# DSS_CTRL register map
Vendor: Texas Instruments
Peripheral module from a debugger description file (folder awr2544).
Registers are 32-bit, read-write, no defined reset value unless marked. A register's access mark holds for its fields unless they carry their own. Offsets are as the file gives them; lines under a group give offsets from that group; [hi:lo] are bit positions; {n}, {i} and the like mark numbered series; 'fields as' and 'values as' point back to an identical list; <NAME> marks a mode.

## DSS_CTRL
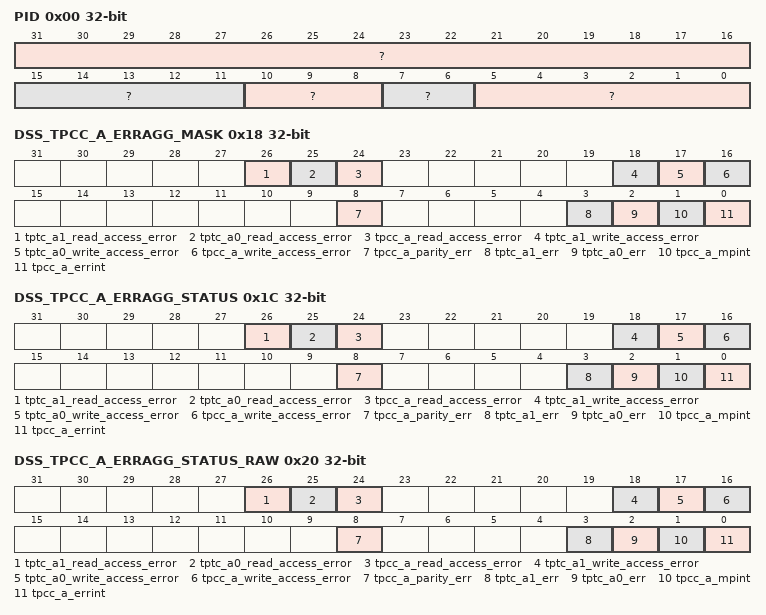
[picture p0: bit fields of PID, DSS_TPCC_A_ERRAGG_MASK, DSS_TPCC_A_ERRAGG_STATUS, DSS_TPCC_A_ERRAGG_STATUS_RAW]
0x00 PID ro
  [31:16] ?, [15:11] ?, [10:8] ?, [7:6] ?, [5:0] ?
0x04 HW_REG0
  [31:0] hwreg0 — Reserved for R&D
0x08 HW_REG1
  [31:0] hwreg1 — Reserved for R&D
0x0C PREVIOUS_NAME
  [31:0] hwreg2 — Reserved for R&D
0x10 HW_REG3
  [31:0] hwreg3 — Reserved for R&D
0x14 DSS_SW_INT
  [3:0] dss_swint — Write pulse bit field: DSS SW Interrupt Write 1 : Generate an interrupt on DSS_SW_INT0
0x18 DSS_TPCC_A_ERRAGG_MASK
  [26] tptc_a1_read_access_error — Mask Interrupt from DSS_TPTC_A1 to aggregated Interrupt DSS_TPCC_A_INTAGG 1 : Interrupt is Masked 0 : Interrupt is Unmasked
  [25] tptc_a0_read_access_error — Mask Interrupt from DSS_TPTC_A0 to aggregated Interrupt DSS_TPCC_A_INTAGG 1 : Interrupt is Masked 0 : Interrupt is Unmasked
  [24] tpcc_a_read_access_error — Mask Interrupt from DSS_TPCC_A to aggregated Interrupt DSS_TPCC_A_INTAGG 1 : Interrupt is Masked 0 : Interrupt is Unmasked
  [18] tptc_a1_write_access_error — Mask Interrupt from DSS_TPTC_A1 to aggregated Interrupt DSS_TPTC_A_INTAGG 1 : Interrupt is Masked 0 : Interrupt is Unmasked
  [17] tptc_a0_write_access_error — Mask Interrupt from DSS_TPTC_A0 to aggregated Interrupt DSS_TPTC_A_INTAGG 1 : Interrupt is Masked 0 : Interrupt is Unmasked
  [16] tpcc_a_write_access_error — Mask Interrupt from DSS_TPCC_A to aggregated Interrupt DSS_TPCC_A_INTAGG 1 : Interrupt is Masked 0 : Interrupt is Unmasked
  [8] tpcc_a_parity_err — Mask Interrupt from DSS_TPCC_A to aggregated Interrupt DSS_TPCC_A_INTAGG 1 : Interrupt is Masked 0 : Interrupt is Unmasked
  [3] tptc_a1_err — Mask Interrupt from DSS_TPTC_A1 to aggregated Interrupt DSS_TPCC_A_INTAGG 1 : Interrupt is Masked 0 : Interrupt is Unmasked
  [2] tptc_a0_err — Mask Interrupt from DSS_TPTC_A0 to aggregated Interrupt DSS_TPCC_A_INTAGG 1 : Interrupt is Masked 0 : Interrupt is Unmasked
  [1] tpcc_a_mpint — Mask Interrupt from DSS_TPCC_A to aggregated Interrupt DSS_TPCC_A_INTAGG 1 : Interrupt is Masked 0 : Interrupt is Unmasked
  [0] tpcc_a_errint — Mask Interrupt from DSS_TPCC_A to aggregated Interrupt DSS_TPCC_A_INTAGG 1 : Interrupt is Masked 0 : Interrupt is Unmasked
0x1C DSS_TPCC_A_ERRAGG_STATUS
  [26] tptc_a1_read_access_error — Status of Interrupt from DSS_TPTC_A1. Set only if Interupt is unmasked in DSS_TPCC_A_INTAGG_MASK Wrie 0x1 to clear this interrupt.
  [25] tptc_a0_read_access_error — Status of Interrupt from DSS_TPTC_A0. Set only if Interupt is unmasked in DSS_TPCC_A_INTAGG_MASK Wrie 0x1 to clear this interrupt.
  [24] tpcc_a_read_access_error — Status of Interrupt from DSS_TPCC_A. Set only if Interupt is unmasked in DSS_TPCC_A_INTAGG_MASK Wrie 0x1 to clear this interrupt.
  [18] tptc_a1_write_access_error — Status of Interrupt from DSS_TPTC_A1. Set only if Interupt is unmasked in DSS_TPTC_A_INTAGG_MASK Wrie 0x1 to clear this interrupt.
  [17] tptc_a0_write_access_error — Status of Interrupt from DSS_TPTC_A0. Set only if Interupt is unmasked in DSS_TPTC_A_INTAGG_MASK Wrie 0x1 to clear this interrupt.
  [16] tpcc_a_write_access_error — Status of Interrupt from DSS_TPCC_A. Set only if Interupt is unmasked in DSS_TPCC_A_INTAGG_MASK Wrie 0x1 to clear this interrupt.
  [8] tpcc_a_parity_err — Status of Interrupt from DSS_TPCC_A. Set only if Interupt is unmasked in DSS_TPCC_A_INTAGG_MASK Wrie 0x1 to clear this interrupt.
  [3] tptc_a1_err — Status of Interrupt from DSS_TPTC_A1. Set only if Interupt is unmasked in DSS_TPCC_A_INTAGG_MASK Wrie 0x1 to clear this interrupt.
  [2] tptc_a0_err — Status of Interrupt from DSS_TPTC_A0. Set only if Interupt is unmasked in DSS_TPCC_A_INTAGG_MASK Wrie 0x1 to clear this interrupt.
  [1] tpcc_a_mpint — Status of Interrupt from DSS_TPCC_A. Set only if Interupt is unmasked in DSS_TPCC_A_INTAGG_MASK Wrie 0x1 to clear this interrupt.
  [0] tpcc_a_errint — Status of Interrupt from DSS_TPCC_A. Set only if Interupt is unmasked in DSS_TPCC_A_INTAGG_MASK Wrie 0x1 to clear this interrupt.
0x20 DSS_TPCC_A_ERRAGG_STATUS_RAW
  [26] tptc_a1_read_access_error — Raw Status of Interrupt from DSS_TPTC_A1. Set irrespective if the Interupt is masked or unmasked in DSS_TPCC_A_INTAGG_MASK
  [25] tptc_a0_read_access_error — Raw Status of Interrupt from DSS_TPTC_A0. Set irrespective if the Interupt is masked or unmasked in DSS_TPCC_A_INTAGG_MASK
  [24] tpcc_a_read_access_error — Raw Status of Interrupt from DSS_TPCC_A. Set irrespective if the Interupt is masked or unmasked in DSS_TPCC_A_INTAGG_MASK
  [18] tptc_a1_write_access_error — Raw Status of Interrupt from DSS_TPTC_A1. Set irrespective if the Interupt is masked or unmasked in DSS_TPTC_A_INTAGG_MASK
  [17] tptc_a0_write_access_error — Raw Status of Interrupt from DSS_TPTC_A0. Set irrespective if the Interupt is masked or unmasked in DSS_TPTC_A_INTAGG_MASK
  [16] tpcc_a_write_access_error — Raw Status of Interrupt from DSS_TPCC_A. Set irrespective if the Interupt is masked or unmasked in DSS_TPCC_A_INTAGG_MASK
  [8] tpcc_a_parity_err — Raw Status of Interrupt from DSS_TPCC_A. Set irrespective if the Interupt is masked or unmasked in DSS_TPCC_A_INTAGG_MASK
  [3] tptc_a1_err — Raw Status of Interrupt from DSS_TPTC_A1. Set irrespective if the Interupt is masked or unmasked in DSS_TPCC_A_INTAGG_MASK
  [2] tptc_a0_err — Raw Status of Interrupt from DSS_TPTC_A0. Set irrespective if the Interupt is masked or unmasked in DSS_TPCC_A_INTAGG_MASK
  [1] tpcc_a_mpint — Raw Status of Interrupt from DSS_TPCC_A. Set irrespective if the Interupt is masked or unmasked in DSS_TPCC_A_INTAGG_MASK
  [0] tpcc_a_errint — Raw Status of Interrupt from DSS_TPCC_A. Set irrespective if the Interupt is masked or unmasked in DSS_TPCC_A_INTAGG_MASK
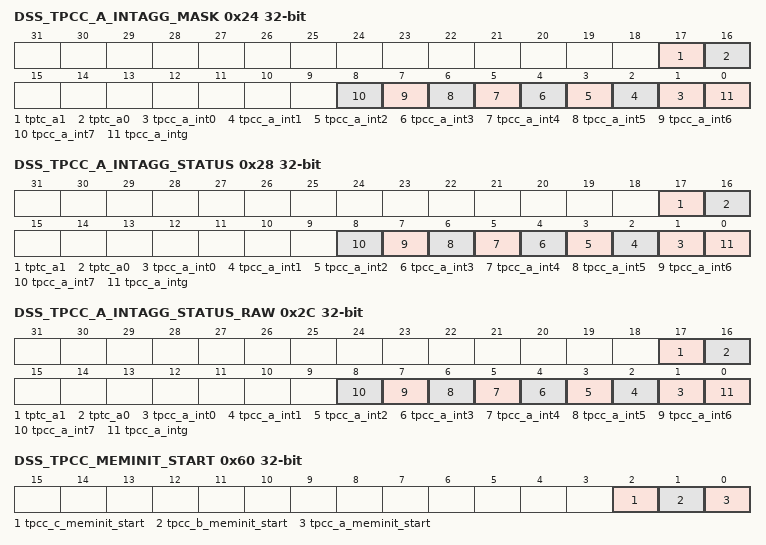
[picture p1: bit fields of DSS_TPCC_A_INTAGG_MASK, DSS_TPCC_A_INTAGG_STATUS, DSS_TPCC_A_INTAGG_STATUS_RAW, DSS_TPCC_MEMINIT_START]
0x24 DSS_TPCC_A_INTAGG_MASK
  [17] tptc_a1 — Mask Interrupt from DSS_TPTC_A1 to aggregated Interrupt DSS_TPCC_A_INTAGG 1 : Interrupt is Masked 0 : Interrupt is Unmasked
  [16] tptc_a0 — Mask Interrupt from DSS_TPTC_A0 to aggregated Interrupt DSS_TPCC_A_INTAGG 1 : Interrupt is Masked 0 : Interrupt is Unmasked
  [n+1] tpcc_a_int{n} (n=0..7) — Mask Interrupt from DSS_TPCC_A to aggregated Interrupt DSS_TPCC_A_INTAGG 1 : Interrupt is Masked 0 : Interrupt is Unmasked
  [0] tpcc_a_intg — Mask Interrupt from DSS_TPCC_A to aggregated Interrupt DSS_TPCC_A_INTAGG 1 : Interrupt is Masked 0 : Interrupt is Unmasked
0x28 DSS_TPCC_A_INTAGG_STATUS
  [17] tptc_a1 — Status of Interrupt from DSS_TPTC_A1. Set only if Interupt is unmasked in DSS_TPCC_A_INTAGG_MASK Wrie 0x1 to clear this interrupt.
  [16] tptc_a0 — Status of Interrupt from DSS_TPTC_A0. Set only if Interupt is unmasked in DSS_TPCC_A_INTAGG_MASK Wrie 0x1 to clear this interrupt.
  [n+1] tpcc_a_int{n} (n=0..7) — Status of Interrupt from DSS_TPCC_A. Set only if Interupt is unmasked in DSS_TPCC_A_INTAGG_MASK Wrie 0x1 to clear this interrupt.
  [0] tpcc_a_intg — Status of Interrupt from DSS_TPCC_A. Set only if Interupt is unmasked in DSS_TPCC_A_INTAGG_MASK Wrie 0x1 to clear this interrupt.
0x2C DSS_TPCC_A_INTAGG_STATUS_RAW
  [17] tptc_a1 — Raw Status of Interrupt from DSS_TPTC_A1. Set irrespective if the Interupt is masked or unmasked in DSS_TPCC_A_INTAGG_MASK
  [16] tptc_a0 — Raw Status of Interrupt from DSS_TPTC_A0. Set irrespective if the Interupt is masked or unmasked in DSS_TPCC_A_INTAGG_MASK
  [n+1] tpcc_a_int{n} (n=0..7) — Raw Status of Interrupt from DSS_TPCC_A. Set irrespective if the Interupt is masked or unmasked in DSS_TPCC_A_INTAGG_MASK
  [0] tpcc_a_intg — Raw Status of Interrupt from DSS_TPCC_A. Set irrespective if the Interupt is masked or unmasked in DSS_TPCC_A_INTAGG_MASK
0x60 DSS_TPCC_MEMINIT_START
  [2] tpcc_c_meminit_start — RESERVED: Dont Use
  [1] tpcc_b_meminit_start — RESERVED: Dont Use
  [0] tpcc_a_meminit_start — Write pulse bit field: Start Memory intialization of TPCC A Param memory. Write 0x1 to start memory initilization. Write 0x0 after ensuring Memory intilization is in progress or has completed. Before starting new initilzation sequence ensure that there is no initilization sequence is in progress (ie TPCC_A_MEMINIT_STATUS should be 0x0) and clear any previouls complettion status(ie write 0x1 to clear TPCC_A_MEMINIT_DONE)
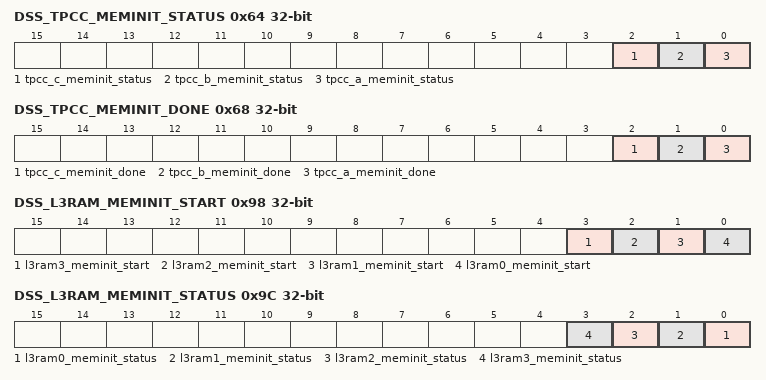
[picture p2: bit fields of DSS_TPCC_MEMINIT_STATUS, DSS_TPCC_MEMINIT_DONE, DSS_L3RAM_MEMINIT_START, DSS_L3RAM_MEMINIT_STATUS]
0x64 DSS_TPCC_MEMINIT_STATUS ro
  [2] tpcc_c_meminit_status — RESERVED: Dont Use
  [1] tpcc_b_meminit_status — RESERVED: Dont Use
  [0] tpcc_a_meminit_status — Status field. Read value 0x1 indicates previously triggered Memory intialization of TPCC A Param memory is in progress.
0x68 DSS_TPCC_MEMINIT_DONE
  [2] tpcc_c_meminit_done — RESERVED: Dont Use
  [1] tpcc_b_meminit_done — RESERVED: Dont Use
  [0] tpcc_a_meminit_done — Status field. Read value 0x1 indicates previously triggered Memory intialization of TPCC A Param memory is complte. Write 0x1 to clear status. Refer TPCC Memory initialization sequnce in EDMA section for more details
0x98 DSS_L3RAM_MEMINIT_START
  [3] l3ram3_meminit_start — Start Memory intialization of TPCC A Param memory. Write 0x1 to start memory initilization. Write 0x0 after ensuring Memory intilization is in progress or has completed. Before starting new initilzation sequence ensure that there is no initilization sequence is in progress (ie L3RAM_MEMINIT_STATUS should be 0x0) and clear any previouls complettion status(ie write 0x1 to clear L3RAM_MEMINIT_DONE)
  [2] l3ram2_meminit_start — Write pulse bit field: Start Memory intialization of TPCC A Param memory. Write 0x1 to start memory initilization. Write 0x0 after ensuring Memory intilization is in progress or has completed. Before starting new initilzation sequence ensure that there is no initilization sequence is in progress (ie L3RAM_MEMINIT_STATUS should be 0x0) and clear any previouls complettion status(ie write 0x1 to clear L3RAM_MEMINIT_DONE)
  [1] l3ram1_meminit_start — Write pulse bit field: Start Memory intialization of TPCC A Param memory. Write 0x1 to start memory initilization. Write 0x0 after ensuring Memory intilization is in progress or has completed. Before starting new initilzation sequence ensure that there is no initilization sequence is in progress (ie L3RAM_MEMINIT_STATUS should be 0x0) and clear any previouls complettion status(ie write 0x1 to clear L3RAM_MEMINIT_DONE)
  [0] l3ram0_meminit_start — Write pulse bit field: Start Memory intialization of TPCC A Param memory. Write 0x1 to start memory initilization. Write 0x0 after ensuring Memory intilization is in progress or has completed. Before starting new initilzation sequence ensure that there is no initilization sequence is in progress (ie L3RAM_MEMINIT_STATUS should be 0x0) and clear any previouls complettion status(ie write 0x1 to clear L3RAM_MEMINIT_DONE)
0x9C DSS_L3RAM_MEMINIT_STATUS ro
  [n] l3ram{n}_meminit_status (n=0..3) — Status field. Read value 0x1 indicates previously triggered Memory intialization of TPCC A Param memory is in progress.
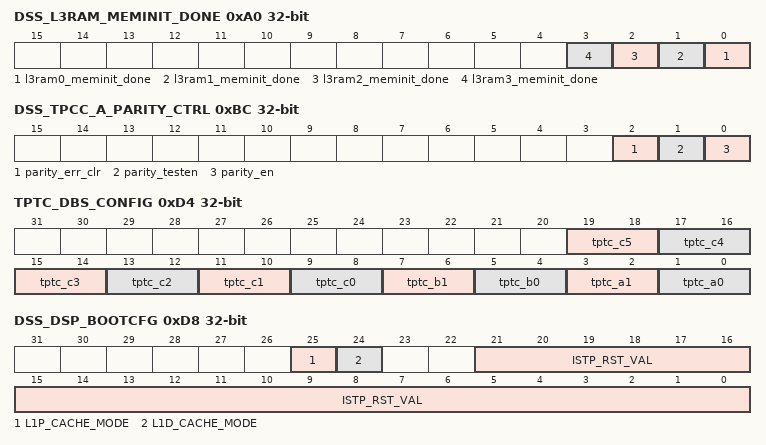
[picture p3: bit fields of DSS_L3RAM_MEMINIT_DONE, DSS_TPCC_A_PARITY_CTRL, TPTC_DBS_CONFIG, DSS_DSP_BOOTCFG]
0xA0 DSS_L3RAM_MEMINIT_DONE
  [n] l3ram{n}_meminit_done (n=0..3) — Status field. Read value 0x1 indicates previously triggered Memory intialization of TPCC A Param memory is complte. Write 0x1 to clear status. Refer TPCC Memory initialization sequnce in EDMA section for more details
0xBC DSS_TPCC_A_PARITY_CTRL
  [2] parity_err_clr — Write pulse bit field: Write 0x1 to clear the Parit Error status for TPCC
  [1] parity_testen — Enable Parity Test for TPCC. Write 0x1 : Parity Test is enabled on PARAM memory
  [0] parity_en — Enable Parity for TPCC. Write 0x1 : Parity is enabled on PARAM memory
0xC8 DSS_TPCC_A_PARITY_STATUS ro
  [7:0] parity_addr — TPCC Error Address at which Parity Error occurred
0xD4 TPTC_DBS_CONFIG
  [2n+9:2n+8] tptc_c{n} (n=1..5) — RESERVED: Dont Use
  [9:8] tptc_c0 — RESERVED: Dont Use0
  [7:6] tptc_b1 — RESERVED: Dont Use
  [5:4] tptc_b0 — RESERVED: Dont Use
  [3:2] tptc_a1 — Max Burst size tieoff value for TPTC A1
  [1:0] tptc_a0 — Max Burst size tieoff value for TPTC A0
0xD8 DSS_DSP_BOOTCFG
  [25] L1P_CACHE_MODE — DSP Boot Configuration : L1P Cache Mode
  [24] L1D_CACHE_MODE — DSP Boot Configuration : L1D Cache Mode
  [21:0] ISTP_RST_VAL — DSP Boot Configuration : Reset Vector
0xDC DSS_DSP_NMI_GATE
  [2:0] gate — Write 3b111 to gate the Non Maskable Interrupt to the DSP. This is not expected to be used
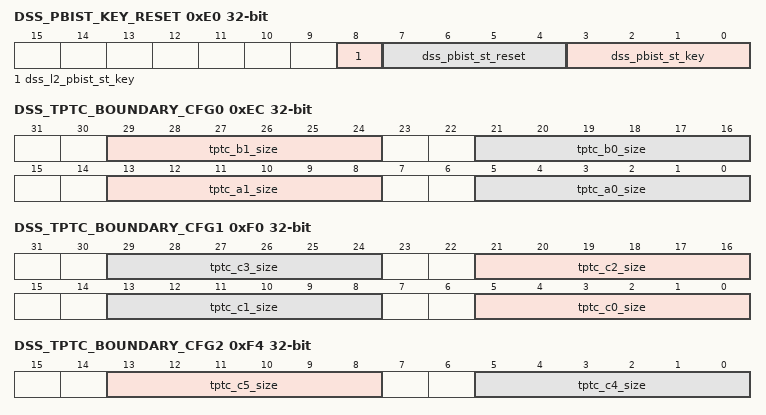
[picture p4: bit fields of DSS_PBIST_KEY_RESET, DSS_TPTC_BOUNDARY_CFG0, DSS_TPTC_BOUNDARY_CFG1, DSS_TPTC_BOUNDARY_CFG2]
0xE0 DSS_PBIST_KEY_RESET
  [8] dss_l2_pbist_st_key — DSS L2 PBIST Selftest Key.
  [7:4] dss_pbist_st_reset — DSS PBIST controller will be brought out of reset when value is 0xA
  [3:0] dss_pbist_st_key — DSS PBIST Selftest Key. Valid value is 0x5
0xE4 DSS_PBIST_REG0
  [31:0] dss_pbist_reg0 — DSP PBIST registers
0xE8 DSS_PBIST_REG1
  [31:0] dss_pbist_reg1 — DSP PBIST registers
0xEC DSS_TPTC_BOUNDARY_CFG0
  [29:24] tptc_b1_size — RESERVED: Dont Use
  [21:16] tptc_b0_size — RESERVED: Dont Use
  [13:8] tptc_a1_size — 6 bit signal used for deciding the boundary crossing size for CID-RID-SID reordering of TPTC Example: writing 6d19 decidies boundary to be 2^19 i.e. 512 KB
  [5:0] tptc_a0_size — 6 bit signal used for deciding the boundary crossing size for CID-RID-SID reordering of TPTC Example: writing 6d19 decidies boundary to be 2^19 i.e. 512 KB
0xF0 DSS_TPTC_BOUNDARY_CFG1
  [8n+5:8n] tptc_c{n}_size (n=0..3) — RESERVED: Dont Use
0xF4 DSS_TPTC_BOUNDARY_CFG2
  [13:8] tptc_c5_size — RESERVED: Dont Use
  [5:0] tptc_c4_size — RESERVED: Dont Use
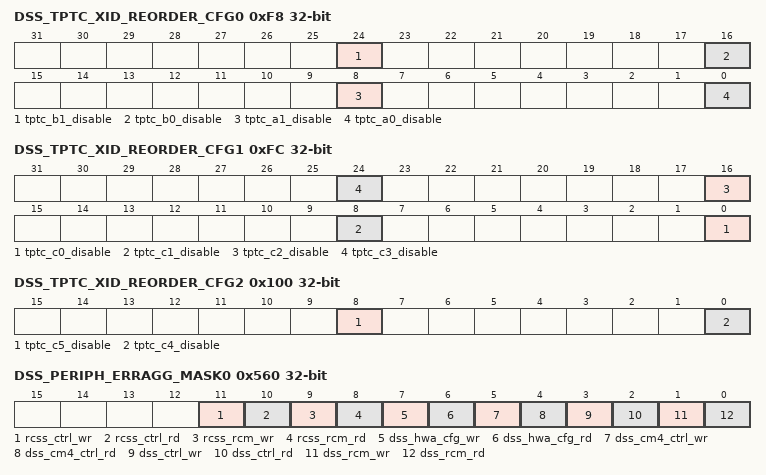
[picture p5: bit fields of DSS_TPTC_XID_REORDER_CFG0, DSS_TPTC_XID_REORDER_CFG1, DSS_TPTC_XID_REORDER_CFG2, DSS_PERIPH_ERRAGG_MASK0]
0xF8 DSS_TPTC_XID_REORDER_CFG0
  [24] tptc_b1_disable — RESERVED: Dont Use
  [16] tptc_b0_disable — RESERVED: Dont Use
  [8] tptc_a1_disable — Writing 1b1 will disable the CID-RID-SID reodering feature for the TPTC instance
  [0] tptc_a0_disable — Writing 1b1 will disable the CID-RID-SID reodering feature for the TPTC instance
0xFC DSS_TPTC_XID_REORDER_CFG1
  [8n] tptc_c{n}_disable (n=0..3) — RESERVED: Dont Use
0x100 DSS_TPTC_XID_REORDER_CFG2
  [8] tptc_c5_disable — RESERVED: Dont Use
  [0] tptc_c4_disable — RESERVED: Dont Use
{0x108+4i} ESM_GATING{i} (i=0..3)
  [31:0] esm_gating — Bit3:0 : writing 000 will ungate the DSS ESM Group2 Error {8i} Bit7:4 : writing 000 will ungate the DSS ESM Group2 Error {8i+1} Bit31:28 : writing 000 will ungate the DSS ESM Group2 Error {8i+7}
0x560 DSS_PERIPH_ERRAGG_MASK0
  [11] rcss_ctrl_wr — Mask the Write error from RCSS_CTRL space from generating an error DSS_PERIPH_ERRAGG to the Processor
  [10] rcss_ctrl_rd — Mask the Read error from RCSS_CTRL space from generating an error DSS_PERIPH_ERRAGG to the Processor
  [9] rcss_rcm_wr — Mask the Write error from RCSS_RCM space from generating an error DSS_PERIPH_ERRAGG to the Processor
  [8] rcss_rcm_rd — Mask the Read error from RCSS_RCM space from generating an error DSS_PERIPH_ERRAGG to the Processor
  [7] dss_hwa_cfg_wr — Mask the Write error from DSS_HWA_CFG space from generating an error DSS_PERIPH_ERRAGG to the Processor
  [6] dss_hwa_cfg_rd — Mask the Read error from DSS_HWA_CFG space from generating an error DSS_PERIPH_ERRAGG to the Processor
  [5] dss_cm4_ctrl_wr — Mask the Write error from DSS_CM4_CTRL space from generating an error DSS_PERIPH_ERRAGG to the Processor
  [4] dss_cm4_ctrl_rd — Mask the Read error from DSS_CM4_CTRL space from generating an error DSS_PERIPH_ERRAGG to the Processor
  [3] dss_ctrl_wr — Mask the Write error from DSS_CTRL space from generating an error DSS_PERIPH_ERRAGG to the Processor
  [2] dss_ctrl_rd — Mask the Read error from DSS_CTRL space from generating an error DSS_PERIPH_ERRAGG to the Processor
  [1] dss_rcm_wr — Mask the Write error from DSS_RCM space from generating an error DSS_PERIPH_ERRAGG to the Processor
  [0] dss_rcm_rd — Mask the Read error from DSS_RCM space from generating an error DSS_PERIPH_ERRAGG to the Processor
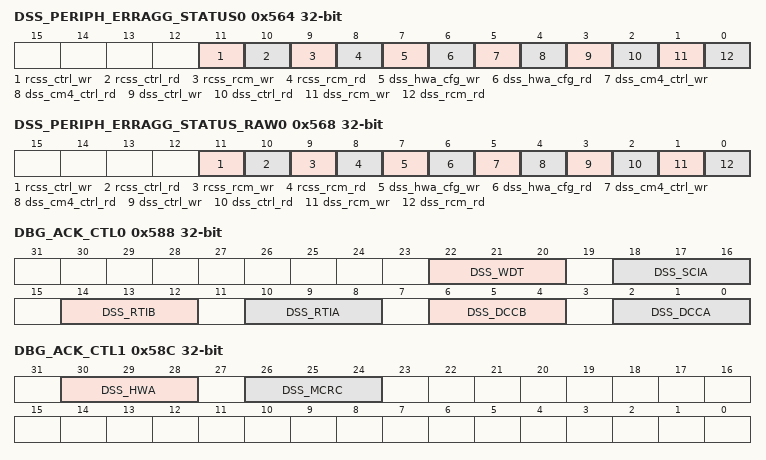
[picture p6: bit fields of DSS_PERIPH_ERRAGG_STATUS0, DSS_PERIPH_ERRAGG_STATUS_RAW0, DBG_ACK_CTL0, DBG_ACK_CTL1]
0x564 DSS_PERIPH_ERRAGG_STATUS0
  [11] rcss_ctrl_wr — Status of the Write error from RCSS_CTRL space. Read 1 : Read error occurred on access to the RCSS_CTRL space
  [10] rcss_ctrl_rd — Status of the Read error from RCSS_CTRL space. Read 1 : Read error occurred on access to the RCSS_CTRL space
  [9] rcss_rcm_wr — Status of the Write error from RCSS_RCM space. Read 1 : Read error occurred on access to the RCSS_RCM space
  [8] rcss_rcm_rd — Status of the Read error from RCSS_RCM space. Read 1 : Read error occurred on access to the RCSS_RCM space
  [7] dss_hwa_cfg_wr — Status of the Write error from DSS_HWA_CFG space. Read 1 : Read error occurred on access to the DSS_HWA_CFG space
  [6] dss_hwa_cfg_rd — Status of the Read error from DSS_HWA_CFG space. Read 1 : Read error occurred on access to the DSS_HWA_CFG space
  [5] dss_cm4_ctrl_wr — Status of the Write error from DSS_CM4_CTRL space. Read 1 : Read error occurred on access to the DSS_CM4_CTRL space
  [4] dss_cm4_ctrl_rd — Status of the Read error from DSS_CM4_CTRL space. Read 1 : Read error occurred on access to the DSS_CM4_CTRL space
  [3] dss_ctrl_wr — Status of the Write error from DSS_CTRL space. Read 1 : Read error occurred on access to the DSS_CTRL space
  [2] dss_ctrl_rd — Status of the Read error from DSS_CTRL space. Read 1 : Read error occurred on access to the DSS_CTRL space
  [1] dss_rcm_wr — Status of the Write error from DSS_RCM space. Read 1 : Read error occurred on access to the DSS_RCM space
  [0] dss_rcm_rd — Status of the Read error from DSS_RCM space. Read 1 : Read error occurred on access to the DSS_RCM space
0x568 DSS_PERIPH_ERRAGG_STATUS_RAW0
  [11] rcss_ctrl_wr — Raw Status of the Write error from RCSS_CTRL space irrespective of it being masked. Read 1 : Read error occurred on access to the RCSS_CTRL space
  [10] rcss_ctrl_rd — Raw Status of the Read error from RCSS_CTRL space irrespective of it being masked. Read 1 : Read error occurred on access to the RCSS_CTRL space
  [9] rcss_rcm_wr — Raw Status of the Write error from RCSS_RCM space irrespective of it being masked. Read 1 : Read error occurred on access to the RCSS_RCM space
  [8] rcss_rcm_rd — Raw Status of the Read error from RCSS_RCM space irrespective of it being masked. Read 1 : Read error occurred on access to the RCSS_RCM space
  [7] dss_hwa_cfg_wr — Raw Status of the Write error from DSS_HWA_CFG space irrespective of it being masked. Read 1 : Read error occurred on access to the DSS_HWA_CFG space
  [6] dss_hwa_cfg_rd — Raw Status of the Read error from DSS_HWA_CFG space irrespective of it being masked. Read 1 : Read error occurred on access to the DSS_HWA_CFG space
  [5] dss_cm4_ctrl_wr — Raw Status of the Write error from DSS_CM4_CTRL space irrespective of it being masked. Read 1 : Read error occurred on access to the DSS_CM4_CTRL space
  [4] dss_cm4_ctrl_rd — Raw Status of the Read error from DSS_CM4_CTRL space irrespective of it being masked. Read 1 : Read error occurred on access to the DSS_CM4_CTRL space
  [3] dss_ctrl_wr — Raw Status of the Write error from DSS_CTRL space irrespective of it being masked. Read 1 : Read error occurred on access to the DSS_CTRL space
  [2] dss_ctrl_rd — Raw Status of the Read error from DSS_CTRL space irrespective of it being masked. Read 1 : Read error occurred on access to the DSS_CTRL space
  [1] dss_rcm_wr — Raw Status of the Write error from DSS_RCM space irrespective of it being masked. Read 1 : Read error occurred on access to the DSS_RCM space
  [0] dss_rcm_rd — Raw Status of the Read error from DSS_RCM space irrespective of it being masked. Read 1 : Read error occurred on access to the DSS_RCM space
0x584 DBG_ACK_CPU_CTRL
  [0] sel — Select the Processor Suspend that is used to Suspend the DSS Peripehrals 0: DSP 1:MSS CR5
0x588 DBG_ACK_CTL0
  [22:20] DSS_WDT — RESERVED: Dont Use
  [18:16] DSS_SCIA — RESERVED: Dont Use
  [14:12] DSS_RTIB — RESERVED: Dont Use
  [10:8] DSS_RTIA — ERESERVED: Dont Use
  [6:4] DSS_DCCB — RESERVED: Dont Use
  [2:0] DSS_DCCA — RESERVED: Dont Use
0x58C DBG_ACK_CTL1
  [30:28] DSS_HWA — Enable Suspend control for the peripheral. 0 :Peripheral not suspended along with processor 1: Peripehal Suspended along with procesor
  [26:24] DSS_MCRC — Enable Suspend control for the peripheral. 0 :Peripheral not suspended along with processor 1: Peripehal Suspended along with procesor
0x590 DSS_DSP_INT_SEL
  [2:0] RCSS_CSI2_ICSSM — DSS DSP Interrupt selcet 0x0: CSI2 Interrupts are propagated to DSP 0x7 : ICSSM Interrupts are propagted to DSP
0x594 DSS_CBUFF_TRIGGER_SEL
  [6:0] sel — DSS CBUFF HW Trigger select from DSS DSP Interrupt Map. Reset value selects RSS_ADC_CAPTURE_COMPLETE as cbuff trigger
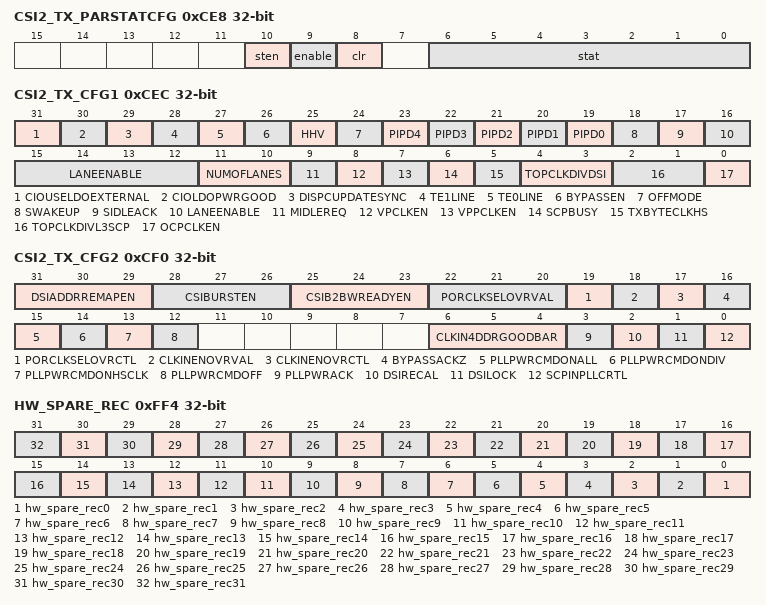
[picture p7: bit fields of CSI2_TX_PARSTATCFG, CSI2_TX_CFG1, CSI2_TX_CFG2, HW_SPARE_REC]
0xCE8 CSI2_TX_PARSTATCFG access per field
  [10] sten rw — Enable bit for the self test of the Parity logic in CSI2
  [9] enable rw — Enable bit for the Parity computation in CSI2
  [8] clr rw — Clear bit for the Parity error from CSI2
  [6:0] stat ro — Parity address from CSI2
0xCEC CSI2_TX_CFG1 access per field
  [31] CIOUSELDOEXTERNAL ro — Connected to dsi_protocol port name csi_ciouseldoexternal
  [30] CIOLDOPWRGOOD rw — Connected to dsi_protocol port name csi_cioldopwrgood
  [29] DISPCUPDATESYNC rw — Connected to dsi_protocol port name csi_dispcupdatesync
  [28] TE1LINE rw — Connected to dsi_protocol port name csi_te1line
  [27] TE0LINE rw — Connected to dsi_protocol port name csi_te0line
  [26] BYPASSEN rw — Connected to dsi_protocol port name csi_bypassen
  [25] HHV rw — Connected to dsi_protocol port name csi_hhv
  [24] OFFMODE rw — Connected to dsi_protocol port name csi_offmode
  [n+19] PIPD{n} rw (n=0..4) — Connected to dsi_protocol port name csi_pipd{n}
  [18] SWAKEUP ro — Connected to dsi_protocol port name csi_po_swakeup
  [17] SIDLEACK ro — Connected to dsi_protocol port name csi_po_sidleack
  [16:12] LANEENABLE rw — Connected to dsi_protocol port name csi_laneenable
  [11:10] NUMOFLANES rw — Connected to dsi_protocol port name csi_numoflanes
  [9] MIDLEREQ rw — Connected to dsi_protocol port name csi_pi_midlereq
  [8] VPCLKEN rw — Connected to dsi_protocol port name mem_vp_clk_en
  [7] VPPCLKEN rw — Connected to dsi_protocol port name mem_vp_pclk_en
  [6] SCPBUSY rw — Connected to dsi_protocol port name csi_pi_scpbusy
  [5] TXBYTECLKHS rw — Connected to dsi_protocol port name csi_pi_top_clkdiv_txbyteclkhs
  [4:3] TOPCLKDIVDSI rw — Connected to dsi_protocol port name csi_pi_top_clkdiv_dsi
  [2:1] TOPCLKDIVL3SCP rw — Connected to dsi_protocol port name csi_pi_top_clkdiv_l3scp
  [0] OCPCLKEN rw — Connected to dsi_protocol port name csi_pi_ocp_clken
0xCF0 CSI2_TX_CFG2 access per field
  [31:29] DSIADDRREMAPEN rw — Enable to Mux the re-mapped addresses for bypass access path to CSI. 000 -->Disable, 111-->Enable, Others are reserved.
  [28:26] CSIBURSTEN rw — Enable to Mux the Burst related signals onto the MSB address bits to the VBUS2OCP module. 000 -->Disable, 111-->Enable, Others are reserved.
  [25:23] CSIB2BWREADYEN rw — Enable for the burst mode support of VBUSP 2 OCP module. 000 -->Disable, 111-->Enable, Others are reserved.
  [22:20] PORCLKSELOVRVAL rw — Override value for CLKLANEADDR port of DSI PHY.
  [19] PORCLKSELOVRCTL rw — Override control for CLKLANEADDR port of DSI PHY.
  [18] CLKINENOVRVAL rw — Override value for CLKINEN port of DSI PHY. Invert of this value is connected to DSI PHY
  [17] CLKINENOVRCTL rw — Override control for CLKINEN port of DSI PHY
  [16] BYPASSACKZ ro — Connected to DSI PHY csi_bypassackz
  [15] PLLPWRCMDONALL ro — Connected to dsi_protocol port name csi_pllpwrcmdonall
  [14] PLLPWRCMDONDIV ro — Connected to dsi_protocol port name csi_pllpwrcmdondiv
  [13] PLLPWRCMDONHSCLK ro — Connected to dsi_protocol port name csi_pllpwrcmdonhsclk
  [12] PLLPWRCMDOFF ro — Connected to dsi_protocol port name csi_pllpwrcmdoff
  [6:4] CLKIN4DDRGOODBAR rw — Connected to DSI PHY csi_clkin4ddrgoodbar
  [3] PLLPWRACK rw — Connected to dsi_protocol port name csi_pllpwrack
  [2] DSIRECAL rw — Connected to dsi_protocol port name csi_dsirecal
  [1] DSILOCK rw — Connected to dsi_protocol port name csi_dsilock
  [0] SCPINPLLCRTL rw — Connected to dsi_protocol port name csi_scpinpllcrtl
{0xFD0+4i} HW_SPARE_RW{i} (i=0..3)
  [31:0] hw_spare_rw{i} — Reserved for HW R&D
{0xFE0+4i} HW_SPARE_RO{i} ro (i=0..3)
  [31:0] hw_spare_ro{i} — Reserved for HW R&D
0xFF4 HW_SPARE_REC
  [n] hw_spare_rec{n} (n=0..31) — Reserved for HW R&D
0x1008 LOCK0_KICK0 — - KICK0 component
  [31:0] ?
0x100C LOCK0_KICK1 — - KICK1 component
  [31:0] ?
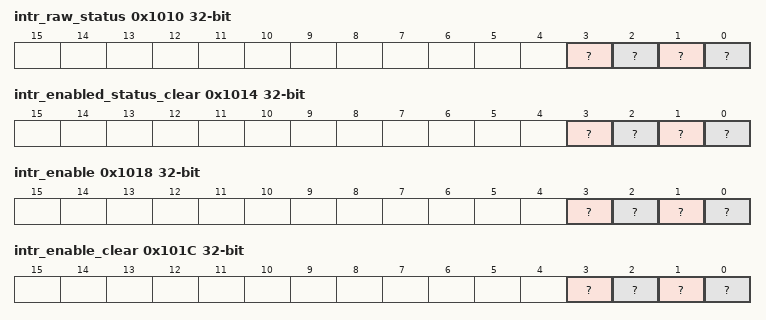
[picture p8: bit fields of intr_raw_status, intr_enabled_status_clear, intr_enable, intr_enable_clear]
0x1010 intr_raw_status — Interrupt Raw Status/Set Register
  [3] ? — Proxy0 access violation error. Raw status is read. Write a 1 to set the status. Writing a 0 has no effect.
  [2] ? — Kick access violation error. Raw status is read. Write a 1 to set the status. Writing a 0 has no effect.
  [1] ? — Addressing violation error. Raw status is read. Write a 1 to set the status. Writing a 0 has no effect.
  [0] ? — Protection violation error. Raw status is read. Write a 1 to set the status. Writing a 0 has no effect.
0x1014 intr_enabled_status_clear — Interrupt Enabled Status/Clear register
  [3] ? — Proxy0 access violation error. Enabled status is read. Write a 1 to clear the status. Writing a 0 has no effect.
  [2] ? — Kick access violation error. Enabled status is read. Write a 1 to clear the status. Writing a 0 has no effect.
  [1] ? — Addressing violation error. Enabled status is read. Write a 1 to clear the status. Writing a 0 has no effect.
  [0] ? — Protection violation error. Enabled status is read. Write a 1 to clear the status. Writing a 0 has no effect.
0x1018 intr_enable — Interrupt Enable register
  [3] ? — Proxy0 access violation error enable. Write a 1 to set the enable. Writing a 0 has no effect.
  [2] ? — Kick access violation error enable. Write a 1 to set the enable. Writing a 0 has no effect.
  [1] ? — Addressing violation error enable. Write a 1 to set the enable. Writing a 0 has no effect.
  [0] ? — Protection violation error enable. Write a 1 to set the enable. Writing a 0 has no effect.
0x101C intr_enable_clear — Interrupt Enable Clear register
  [3] ? — Proxy0 access violation error enable clear. Write a 1 to clear the enable. Writing a 0 has no effect.
  [2] ? — Kick access violation error enable clear. Write a 1 to clear the enable. Writing a 0 has no effect.
  [1] ? — Addressing violation error enable clear. Write a 1 to clear the enable. Writing a 0 has no effect.
  [0] ? — Protection violation error enable clear. Write a 1 to clear the enable. Writing a 0 has no effect.
0x1020 eoi
  [7:0] ? — EOI vector value. Write this with interrupt distribution value in the chip.
0x1024 fault_address ro
  [31:0] ? — Fault Address.
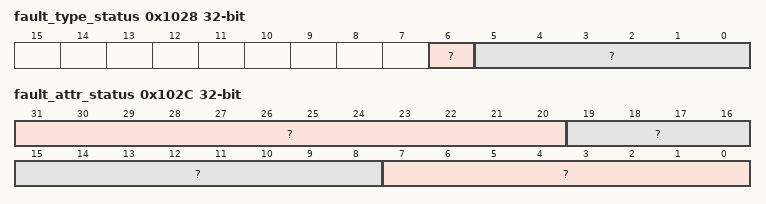
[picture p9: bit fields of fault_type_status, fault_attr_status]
0x1028 fault_type_status ro
  [6] ? — Non-secure access.
  [5:0] ? — Fault Type 10_0000 = Supervisor read fault - priv = 1 dir = 1 dtype != 1 01_0000 = Supervisor write fault - priv = 1 dir = 0 00_1000 = Supervisor execute fault - priv = 1 dir = 1 dtype = 1 00_0100 = User read fault - priv = 0 dir = 1 dtype = 1 00_0010 = User write fault - priv = 0 dir = 0 00_0001 = User execute fault - priv = 0 dir = 1 dtype = 1 00_0000 = No fault
0x102C fault_attr_status ro — Fault Attribute Status register
  [31:20] ? — XID.
  [19:8] ? — Route ID.
  [7:0] ? — Privilege ID.
0x1030 fault_clear wo
  [0] ? — Fault clear. Writing a 1 clears the current fault. Writing a 0 has no effect.
